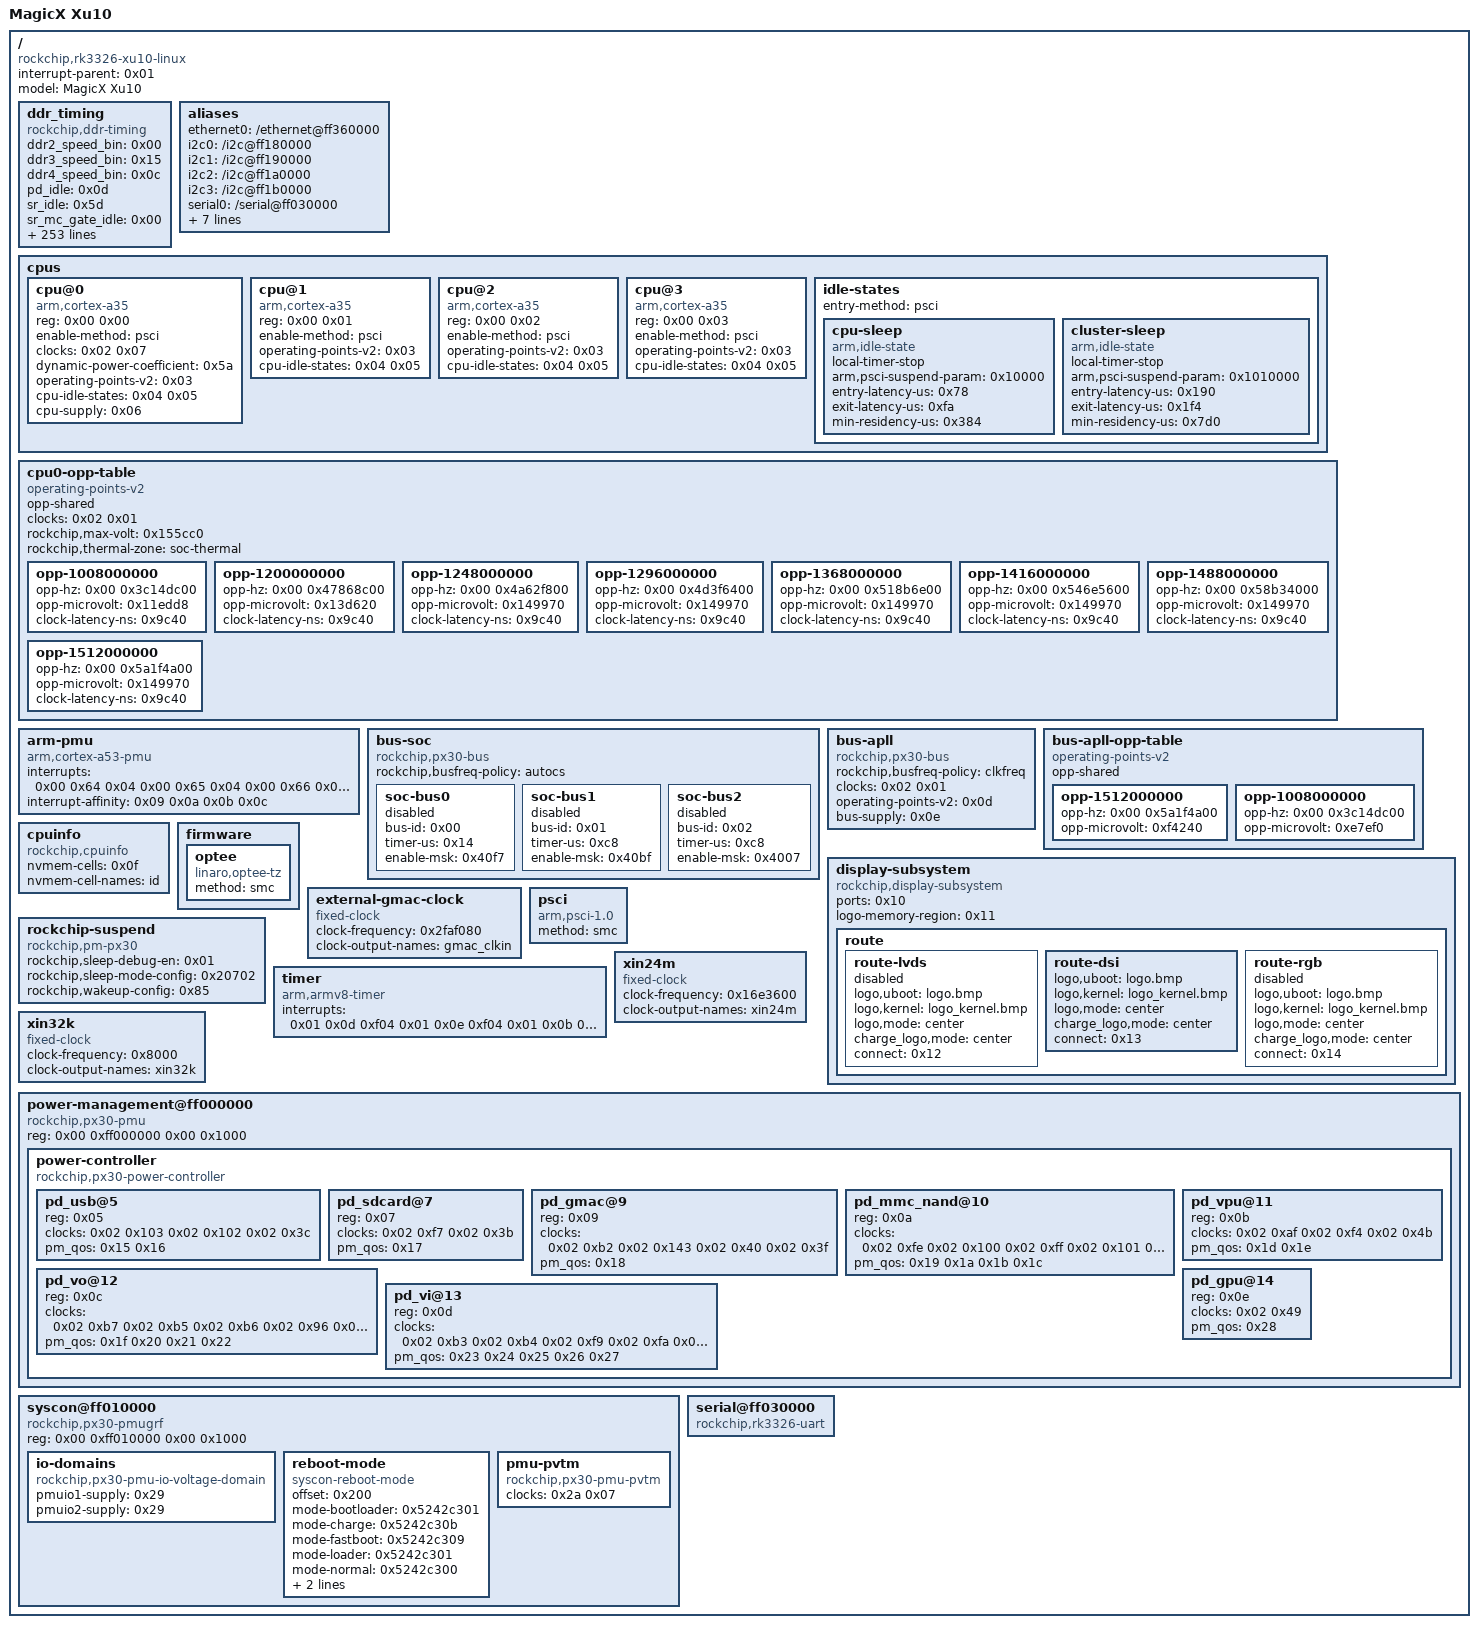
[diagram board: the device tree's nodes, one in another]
/dts-v1/;

/ {
	compatible = "rockchip,rk3326-xu10-linux\0rockchip,rk3326";
	interrupt-parent = <0x01>;
	#address-cells = <0x02>;
	#size-cells = <0x02>;
	model = "MagicX Xu10";

	ddr_timing {
		compatible = "rockchip,ddr-timing";
		ddr2_speed_bin = <0x00>;
		ddr3_speed_bin = <0x15>;
		ddr4_speed_bin = <0x0c>;
		pd_idle = <0x0d>;
		sr_idle = <0x5d>;
		sr_mc_gate_idle = <0x00>;
		srpd_lite_idle = <0x00>;
		standby_idle = <0x00>;
		auto_pd_dis_freq = <0x42a>;
		auto_sr_dis_freq = <0x320>;
		ddr2_dll_dis_freq = <0x12c>;
		ddr3_dll_dis_freq = <0x12c>;
		ddr4_dll_dis_freq = <0x271>;
		phy_dll_dis_freq = <0x190>;
		ddr2_odt_dis_freq = <0x64>;
		phy_ddr2_odt_dis_freq = <0x64>;
		ddr2_drv = <0x01>;
		ddr2_odt = <0x96>;
		phy_ddr2_ca_drv = <0x15>;
		phy_ddr2_ck_drv = <0x12>;
		phy_ddr2_dq_drv = <0x15>;
		phy_ddr2_odt = <0x02>;
		ddr3_odt_dis_freq = <0x190>;
		phy_ddr3_odt_dis_freq = <0x190>;
		ddr3_drv = <0x28>;
		ddr3_odt = <0x78>;
		phy_ddr3_ca_drv = <0x15>;
		phy_ddr3_ck_drv = <0x12>;
		phy_ddr3_dq_drv = <0x15>;
		phy_ddr3_odt = <0x02>;
		phy_lpddr2_odt_dis_freq = <0x29a>;
		lpddr2_drv = <0x28>;
		phy_lpddr2_ca_drv = <0x16>;
		phy_lpddr2_ck_drv = <0x13>;
		phy_lpddr2_dq_drv = <0x16>;
		phy_lpddr2_odt = <0x00>;
		lpddr3_odt_dis_freq = <0x190>;
		phy_lpddr3_odt_dis_freq = <0x190>;
		lpddr3_drv = <0x28>;
		lpddr3_odt = <0xf0>;
		phy_lpddr3_ca_drv = <0x16>;
		phy_lpddr3_ck_drv = <0x13>;
		phy_lpddr3_dq_drv = <0x16>;
		phy_lpddr3_odt = <0x02>;
		lpddr4_odt_dis_freq = <0x320>;
		phy_lpddr4_odt_dis_freq = <0x320>;
		lpddr4_drv = <0x3c>;
		lpddr4_dq_odt = <0x28>;
		lpddr4_ca_odt = <0x28>;
		phy_lpddr4_ca_drv = <0x14>;
		phy_lpddr4_ck_cs_drv = <0x06>;
		phy_lpddr4_dq_drv = <0x06>;
		phy_lpddr4_odt = <0x10>;
		ddr4_odt_dis_freq = <0x29a>;
		phy_ddr4_odt_dis_freq = <0x29a>;
		ddr4_drv = <0x22>;
		ddr4_odt = <0xf0>;
		phy_ddr4_ca_drv = <0x16>;
		phy_ddr4_ck_drv = <0x13>;
		phy_ddr4_dq_drv = <0x16>;
		phy_ddr4_odt = <0x02>;
		ddr3a1_ddr4a9_de-skew = <0x06>;
		ddr3a0_ddr4a10_de-skew = <0x07>;
		ddr3a3_ddr4a6_de-skew = <0x07>;
		ddr3a2_ddr4a4_de-skew = <0x07>;
		ddr3a5_dd4a8_de-skew = <0x07>;
		ddr3a4_ddr4a5_de-skew = <0x07>;
		ddr3a7_ddr4a11_de-skew = <0x07>;
		ddr3a6_ddr4a7_de-skew = <0x06>;
		ddr3a9_ddr4a0_de-skew = <0x07>;
		ddr3a8_ddr4a13_de-skew = <0x07>;
		ddr3a11_ddr4a3_de-skew = <0x07>;
		ddr3a10_ddr4cs0_de-skew = <0x07>;
		ddr3a13_ddr4a2_de-skew = <0x07>;
		ddr3a12_ddr4ba1_de-skew = <0x07>;
		ddr3a15_ddr4odt0_de-skew = <0x07>;
		ddr3a14_ddr4a1_de-skew = <0x07>;
		ddr3ba1_ddr4a15_de-skew = <0x07>;
		ddr3ba0_ddr4bg0_de-skew = <0x07>;
		ddr3ras_ddr4cke_de-skew = <0x07>;
		ddr3ba2_ddr4ba0_de-skew = <0x07>;
		ddr3we_ddr4bg1_de-skew = <0x07>;
		ddr3cas_ddr4a12_de-skew = <0x07>;
		ddr3ckn_ddr4ckn_de-skew = <0x07>;
		ddr3ckp_ddr4ckp_de-skew = <0x07>;
		ddr3cke_ddr4a16_de-skew = <0x07>;
		ddr3odt0_ddr4a14_de-skew = <0x07>;
		ddr3cs0_ddr4act_de-skew = <0x06>;
		ddr3reset_ddr4reset_de-skew = <0x07>;
		ddr3cs1_ddr4cs1_de-skew = <0x06>;
		ddr3odt1_ddr4odt1_de-skew = <0x07>;
		cs0_dm0_rx_de-skew = <0x07>;
		cs0_dm0_tx_de-skew = <0x07>;
		cs0_dq0_rx_de-skew = <0x08>;
		cs0_dq0_tx_de-skew = <0x08>;
		cs0_dq1_rx_de-skew = <0x09>;
		cs0_dq1_tx_de-skew = <0x08>;
		cs0_dq2_rx_de-skew = <0x08>;
		cs0_dq2_tx_de-skew = <0x08>;
		cs0_dq3_rx_de-skew = <0x08>;
		cs0_dq3_tx_de-skew = <0x08>;
		cs0_dq4_rx_de-skew = <0x09>;
		cs0_dq4_tx_de-skew = <0x08>;
		cs0_dq5_rx_de-skew = <0x09>;
		cs0_dq5_tx_de-skew = <0x08>;
		cs0_dq6_rx_de-skew = <0x09>;
		cs0_dq6_tx_de-skew = <0x08>;
		cs0_dq7_rx_de-skew = <0x08>;
		cs0_dq7_tx_de-skew = <0x08>;
		cs0_dqs0_rx_de-skew = <0x06>;
		cs0_dqs0p_tx_de-skew = <0x09>;
		cs0_dqs0n_tx_de-skew = <0x09>;
		cs0_dm1_rx_de-skew = <0x07>;
		cs0_dm1_tx_de-skew = <0x06>;
		cs0_dq8_rx_de-skew = <0x08>;
		cs0_dq8_tx_de-skew = <0x07>;
		cs0_dq9_rx_de-skew = <0x09>;
		cs0_dq9_tx_de-skew = <0x07>;
		cs0_dq10_rx_de-skew = <0x08>;
		cs0_dq10_tx_de-skew = <0x08>;
		cs0_dq11_rx_de-skew = <0x08>;
		cs0_dq11_tx_de-skew = <0x07>;
		cs0_dq12_rx_de-skew = <0x08>;
		cs0_dq12_tx_de-skew = <0x08>;
		cs0_dq13_rx_de-skew = <0x09>;
		cs0_dq13_tx_de-skew = <0x07>;
		cs0_dq14_rx_de-skew = <0x09>;
		cs0_dq14_tx_de-skew = <0x08>;
		cs0_dq15_rx_de-skew = <0x09>;
		cs0_dq15_tx_de-skew = <0x07>;
		cs0_dqs1_rx_de-skew = <0x07>;
		cs0_dqs1p_tx_de-skew = <0x09>;
		cs0_dqs1n_tx_de-skew = <0x09>;
		cs0_dm2_rx_de-skew = <0x07>;
		cs0_dm2_tx_de-skew = <0x07>;
		cs0_dq16_rx_de-skew = <0x09>;
		cs0_dq16_tx_de-skew = <0x09>;
		cs0_dq17_rx_de-skew = <0x07>;
		cs0_dq17_tx_de-skew = <0x09>;
		cs0_dq18_rx_de-skew = <0x07>;
		cs0_dq18_tx_de-skew = <0x08>;
		cs0_dq19_rx_de-skew = <0x07>;
		cs0_dq19_tx_de-skew = <0x09>;
		cs0_dq20_rx_de-skew = <0x09>;
		cs0_dq20_tx_de-skew = <0x09>;
		cs0_dq21_rx_de-skew = <0x09>;
		cs0_dq21_tx_de-skew = <0x09>;
		cs0_dq22_rx_de-skew = <0x08>;
		cs0_dq22_tx_de-skew = <0x09>;
		cs0_dq23_rx_de-skew = <0x08>;
		cs0_dq23_tx_de-skew = <0x09>;
		cs0_dqs2_rx_de-skew = <0x06>;
		cs0_dqs2p_tx_de-skew = <0x09>;
		cs0_dqs2n_tx_de-skew = <0x09>;
		cs0_dm3_rx_de-skew = <0x07>;
		cs0_dm3_tx_de-skew = <0x07>;
		cs0_dq24_rx_de-skew = <0x08>;
		cs0_dq24_tx_de-skew = <0x08>;
		cs0_dq25_rx_de-skew = <0x09>;
		cs0_dq25_tx_de-skew = <0x09>;
		cs0_dq26_rx_de-skew = <0x09>;
		cs0_dq26_tx_de-skew = <0x08>;
		cs0_dq27_rx_de-skew = <0x09>;
		cs0_dq27_tx_de-skew = <0x08>;
		cs0_dq28_rx_de-skew = <0x09>;
		cs0_dq28_tx_de-skew = <0x09>;
		cs0_dq29_rx_de-skew = <0x09>;
		cs0_dq29_tx_de-skew = <0x09>;
		cs0_dq30_rx_de-skew = <0x08>;
		cs0_dq30_tx_de-skew = <0x08>;
		cs0_dq31_rx_de-skew = <0x08>;
		cs0_dq31_tx_de-skew = <0x08>;
		cs0_dqs3_rx_de-skew = <0x07>;
		cs0_dqs3p_tx_de-skew = <0x09>;
		cs0_dqs3n_tx_de-skew = <0x09>;
		cs1_dm0_rx_de-skew = <0x07>;
		cs1_dm0_tx_de-skew = <0x07>;
		cs1_dq0_rx_de-skew = <0x08>;
		cs1_dq0_tx_de-skew = <0x08>;
		cs1_dq1_rx_de-skew = <0x09>;
		cs1_dq1_tx_de-skew = <0x08>;
		cs1_dq2_rx_de-skew = <0x08>;
		cs1_dq2_tx_de-skew = <0x08>;
		cs1_dq3_rx_de-skew = <0x08>;
		cs1_dq3_tx_de-skew = <0x08>;
		cs1_dq4_rx_de-skew = <0x08>;
		cs1_dq4_tx_de-skew = <0x08>;
		cs1_dq5_rx_de-skew = <0x09>;
		cs1_dq5_tx_de-skew = <0x08>;
		cs1_dq6_rx_de-skew = <0x09>;
		cs1_dq6_tx_de-skew = <0x08>;
		cs1_dq7_rx_de-skew = <0x08>;
		cs1_dq7_tx_de-skew = <0x08>;
		cs1_dqs0_rx_de-skew = <0x06>;
		cs1_dqs0p_tx_de-skew = <0x09>;
		cs1_dqs0n_tx_de-skew = <0x09>;
		cs1_dm1_rx_de-skew = <0x07>;
		cs1_dm1_tx_de-skew = <0x07>;
		cs1_dq8_rx_de-skew = <0x08>;
		cs1_dq8_tx_de-skew = <0x08>;
		cs1_dq9_rx_de-skew = <0x08>;
		cs1_dq9_tx_de-skew = <0x07>;
		cs1_dq10_rx_de-skew = <0x07>;
		cs1_dq10_tx_de-skew = <0x08>;
		cs1_dq11_rx_de-skew = <0x08>;
		cs1_dq11_tx_de-skew = <0x08>;
		cs1_dq12_rx_de-skew = <0x08>;
		cs1_dq12_tx_de-skew = <0x07>;
		cs1_dq13_rx_de-skew = <0x08>;
		cs1_dq13_tx_de-skew = <0x08>;
		cs1_dq14_rx_de-skew = <0x08>;
		cs1_dq14_tx_de-skew = <0x08>;
		cs1_dq15_rx_de-skew = <0x08>;
		cs1_dq15_tx_de-skew = <0x07>;
		cs1_dqs1_rx_de-skew = <0x07>;
		cs1_dqs1p_tx_de-skew = <0x09>;
		cs1_dqs1n_tx_de-skew = <0x09>;
		cs1_dm2_rx_de-skew = <0x07>;
		cs1_dm2_tx_de-skew = <0x08>;
		cs1_dq16_rx_de-skew = <0x08>;
		cs1_dq16_tx_de-skew = <0x09>;
		cs1_dq17_rx_de-skew = <0x08>;
		cs1_dq17_tx_de-skew = <0x09>;
		cs1_dq18_rx_de-skew = <0x07>;
		cs1_dq18_tx_de-skew = <0x08>;
		cs1_dq19_rx_de-skew = <0x08>;
		cs1_dq19_tx_de-skew = <0x09>;
		cs1_dq20_rx_de-skew = <0x09>;
		cs1_dq20_tx_de-skew = <0x09>;
		cs1_dq21_rx_de-skew = <0x09>;
		cs1_dq21_tx_de-skew = <0x09>;
		cs1_dq22_rx_de-skew = <0x08>;
		cs1_dq22_tx_de-skew = <0x09>;
		cs1_dq23_rx_de-skew = <0x08>;
		cs1_dq23_tx_de-skew = <0x09>;
		cs1_dqs2_rx_de-skew = <0x06>;
		cs1_dqs2p_tx_de-skew = <0x09>;
		cs1_dqs2n_tx_de-skew = <0x09>;
		cs1_dm3_rx_de-skew = <0x07>;
		cs1_dm3_tx_de-skew = <0x07>;
		cs1_dq24_rx_de-skew = <0x08>;
		cs1_dq24_tx_de-skew = <0x09>;
		cs1_dq25_rx_de-skew = <0x09>;
		cs1_dq25_tx_de-skew = <0x09>;
		cs1_dq26_rx_de-skew = <0x09>;
		cs1_dq26_tx_de-skew = <0x08>;
		cs1_dq27_rx_de-skew = <0x08>;
		cs1_dq27_tx_de-skew = <0x08>;
		cs1_dq28_rx_de-skew = <0x09>;
		cs1_dq28_tx_de-skew = <0x09>;
		cs1_dq29_rx_de-skew = <0x09>;
		cs1_dq29_tx_de-skew = <0x09>;
		cs1_dq30_rx_de-skew = <0x09>;
		cs1_dq30_tx_de-skew = <0x08>;
		cs1_dq31_rx_de-skew = <0x08>;
		cs1_dq31_tx_de-skew = <0x08>;
		cs1_dqs3_rx_de-skew = <0x07>;
		cs1_dqs3p_tx_de-skew = <0x09>;
		cs1_dqs3n_tx_de-skew = <0x09>;
		phandle = <0xb0>;
	};

	aliases {
		ethernet0 = "/ethernet@ff360000";
		i2c0 = "/i2c@ff180000";
		i2c1 = "/i2c@ff190000";
		i2c2 = "/i2c@ff1a0000";
		i2c3 = "/i2c@ff1b0000";
		serial0 = "/serial@ff030000";
		serial1 = "/serial@ff158000";
		serial2 = "/serial@ff160000";
		serial3 = "/serial@ff168000";
		serial4 = "/serial@ff170000";
		serial5 = "/serial@ff178000";
		spi0 = "/spi@ff1d0000";
		spi1 = "/spi@ff1d8000";
	};

	cpus {
		#address-cells = <0x02>;
		#size-cells = <0x00>;

		cpu@0 {
			device_type = "cpu";
			compatible = "arm,cortex-a35\0arm,armv8";
			reg = <0x00 0x00>;
			enable-method = "psci";
			clocks = <0x02 0x07>;
			#cooling-cells = <0x02>;
			dynamic-power-coefficient = <0x5a>;
			operating-points-v2 = <0x03>;
			cpu-idle-states = <0x04 0x05>;
			cpu-supply = <0x06>;
			phandle = <0x09>;
		};

		cpu@1 {
			device_type = "cpu";
			compatible = "arm,cortex-a35\0arm,armv8";
			reg = <0x00 0x01>;
			enable-method = "psci";
			operating-points-v2 = <0x03>;
			cpu-idle-states = <0x04 0x05>;
			phandle = <0x0a>;
		};

		cpu@2 {
			device_type = "cpu";
			compatible = "arm,cortex-a35\0arm,armv8";
			reg = <0x00 0x02>;
			enable-method = "psci";
			operating-points-v2 = <0x03>;
			cpu-idle-states = <0x04 0x05>;
			phandle = <0x0b>;
		};

		cpu@3 {
			device_type = "cpu";
			compatible = "arm,cortex-a35\0arm,armv8";
			reg = <0x00 0x03>;
			enable-method = "psci";
			operating-points-v2 = <0x03>;
			cpu-idle-states = <0x04 0x05>;
			phandle = <0x0c>;
		};

		idle-states {
			entry-method = "psci";

			cpu-sleep {
				compatible = "arm,idle-state";
				local-timer-stop;
				arm,psci-suspend-param = <0x10000>;
				entry-latency-us = <0x78>;
				exit-latency-us = <0xfa>;
				min-residency-us = <0x384>;
				phandle = <0x04>;
			};

			cluster-sleep {
				compatible = "arm,idle-state";
				local-timer-stop;
				arm,psci-suspend-param = <0x1010000>;
				entry-latency-us = <0x190>;
				exit-latency-us = <0x1f4>;
				min-residency-us = <0x7d0>;
				phandle = <0x05>;
			};
		};
	};

	cpu0-opp-table {
		compatible = "operating-points-v2";
		opp-shared;
		clocks = <0x02 0x01>;
		rockchip,max-volt = <0x155cc0>;
		rockchip,thermal-zone = "soc-thermal";
		phandle = <0x03>;

		opp-1008000000 {
			opp-hz = <0x00 0x3c14dc00>;
			opp-microvolt = <0x11edd8>;
			clock-latency-ns = <0x9c40>;
		};

		opp-1200000000 {
			opp-hz = <0x00 0x47868c00>;
			opp-microvolt = <0x13d620>;
			clock-latency-ns = <0x9c40>;
		};

		opp-1248000000 {
			opp-hz = <0x00 0x4a62f800>;
			opp-microvolt = <0x149970>;
			clock-latency-ns = <0x9c40>;
		};

		opp-1296000000 {
			opp-hz = <0x00 0x4d3f6400>;
			opp-microvolt = <0x149970>;
			clock-latency-ns = <0x9c40>;
		};

		opp-1368000000 {
			opp-hz = <0x00 0x518b6e00>;
			opp-microvolt = <0x149970>;
			clock-latency-ns = <0x9c40>;
		};

		opp-1416000000 {
			opp-hz = <0x00 0x546e5600>;
			opp-microvolt = <0x149970>;
			clock-latency-ns = <0x9c40>;
		};

		opp-1488000000 {
			opp-hz = <0x00 0x58b34000>;
			opp-microvolt = <0x149970>;
			clock-latency-ns = <0x9c40>;
		};

		opp-1512000000 {
			opp-hz = <0x00 0x5a1f4a00>;
			opp-microvolt = <0x149970>;
			clock-latency-ns = <0x9c40>;
		};
	};

	arm-pmu {
		compatible = "arm,cortex-a53-pmu";
		interrupts = <0x00 0x64 0x04 0x00 0x65 0x04 0x00 0x66 0x04 0x00 0x67 0x04>;
		interrupt-affinity = <0x09 0x0a 0x0b 0x0c>;
	};

	bus-soc {
		compatible = "rockchip,px30-bus";
		rockchip,busfreq-policy = "autocs";
		phandle = <0xc4>;

		soc-bus0 {
			bus-id = <0x00>;
			timer-us = <0x14>;
			enable-msk = <0x40f7>;
			status = "disabled";
		};

		soc-bus1 {
			bus-id = <0x01>;
			timer-us = <0xc8>;
			enable-msk = <0x40bf>;
			status = "disabled";
		};

		soc-bus2 {
			bus-id = <0x02>;
			timer-us = <0xc8>;
			enable-msk = <0x4007>;
			status = "disabled";
		};
	};

	bus-apll {
		compatible = "rockchip,px30-bus";
		rockchip,busfreq-policy = "clkfreq";
		clocks = <0x02 0x01>;
		clock-names = "bus";
		operating-points-v2 = <0x0d>;
		status = "okay";
		bus-supply = <0x0e>;
		phandle = <0xc5>;
	};

	bus-apll-opp-table {
		compatible = "operating-points-v2";
		opp-shared;
		phandle = <0x0d>;

		opp-1512000000 {
			opp-hz = <0x00 0x5a1f4a00>;
			opp-microvolt = <0xf4240>;
		};

		opp-1008000000 {
			opp-hz = <0x00 0x3c14dc00>;
			opp-microvolt = <0xe7ef0>;
		};
	};

	cpuinfo {
		compatible = "rockchip,cpuinfo";
		nvmem-cells = <0x0f>;
		nvmem-cell-names = "id";
	};

	display-subsystem {
		compatible = "rockchip,display-subsystem";
		ports = <0x10>;
		status = "okay";
		logo-memory-region = <0x11>;
		phandle = <0xc6>;

		route {

			route-lvds {
				status = "disabled";
				logo,uboot = "logo.bmp";
				logo,kernel = "logo_kernel.bmp";
				logo,mode = "center";
				charge_logo,mode = "center";
				connect = <0x12>;
				phandle = <0xc7>;
			};

			route-dsi {
				status = "okay";
				logo,uboot = "logo.bmp";
				logo,kernel = "logo_kernel.bmp";
				logo,mode = "center";
				charge_logo,mode = "center";
				connect = <0x13>;
				phandle = <0xc8>;
			};

			route-rgb {
				status = "disabled";
				logo,uboot = "logo.bmp";
				logo,kernel = "logo_kernel.bmp";
				logo,mode = "center";
				charge_logo,mode = "center";
				connect = <0x14>;
				phandle = <0xc9>;
			};
		};
	};

	firmware {

		optee {
			compatible = "linaro,optee-tz";
			method = "smc";
		};
	};

	external-gmac-clock {
		compatible = "fixed-clock";
		clock-frequency = <0x2faf080>;
		clock-output-names = "gmac_clkin";
		#clock-cells = <0x00>;
		phandle = <0xca>;
	};

	psci {
		compatible = "arm,psci-1.0";
		method = "smc";
	};

	rockchip-suspend {
		compatible = "rockchip,pm-px30";
		status = "okay";
		rockchip,sleep-debug-en = <0x01>;
		rockchip,sleep-mode-config = <0x20702>;
		rockchip,wakeup-config = <0x85>;
		phandle = <0xcb>;
	};

	timer {
		compatible = "arm,armv8-timer";
		interrupts = <0x01 0x0d 0xf04 0x01 0x0e 0xf04 0x01 0x0b 0xf04 0x01 0x0a 0xf04>;
	};

	xin24m {
		compatible = "fixed-clock";
		#clock-cells = <0x00>;
		clock-frequency = <0x16e3600>;
		clock-output-names = "xin24m";
		phandle = <0xcc>;
	};

	xin32k {
		compatible = "fixed-clock";
		#clock-cells = <0x00>;
		clock-frequency = <0x8000>;
		clock-output-names = "xin32k";
		phandle = <0xcd>;
	};

	power-management@ff000000 {
		compatible = "rockchip,px30-pmu\0syscon\0simple-mfd";
		reg = <0x00 0xff000000 0x00 0x1000>;
		phandle = <0xce>;

		power-controller {
			compatible = "rockchip,px30-power-controller";
			#power-domain-cells = <0x01>;
			#address-cells = <0x01>;
			#size-cells = <0x00>;
			phandle = <0x8b>;

			pd_usb@5 {
				reg = <0x05>;
				clocks = <0x02 0x103 0x02 0x102 0x02 0x3c>;
				pm_qos = <0x15 0x16>;
			};

			pd_sdcard@7 {
				reg = <0x07>;
				clocks = <0x02 0xf7 0x02 0x3b>;
				pm_qos = <0x17>;
			};

			pd_gmac@9 {
				reg = <0x09>;
				clocks = <0x02 0xb2 0x02 0x143 0x02 0x40 0x02 0x3f>;
				pm_qos = <0x18>;
			};

			pd_mmc_nand@10 {
				reg = <0x0a>;
				clocks = <0x02 0xfe 0x02 0x100 0x02 0xff 0x02 0x101 0x02 0x39 0x02 0x37 0x02 0x38 0x02 0x3a>;
				pm_qos = <0x19 0x1a 0x1b 0x1c>;
			};

			pd_vpu@11 {
				reg = <0x0b>;
				clocks = <0x02 0xaf 0x02 0xf4 0x02 0x4b>;
				pm_qos = <0x1d 0x1e>;
			};

			pd_vo@12 {
				reg = <0x0c>;
				clocks = <0x02 0xb7 0x02 0xb5 0x02 0xb6 0x02 0x96 0x02 0x97 0x02 0xfd 0x02 0xfb 0x02 0xfc 0x02 0x144 0x02 0x35 0x02 0x36>;
				pm_qos = <0x1f 0x20 0x21 0x22>;
			};

			pd_vi@13 {
				reg = <0x0d>;
				clocks = <0x02 0xb3 0x02 0xb4 0x02 0xf9 0x02 0xfa 0x02 0x33>;
				pm_qos = <0x23 0x24 0x25 0x26 0x27>;
			};

			pd_gpu@14 {
				reg = <0x0e>;
				clocks = <0x02 0x49>;
				pm_qos = <0x28>;
			};
		};
	};

	syscon@ff010000 {
		compatible = "rockchip,px30-pmugrf\0syscon\0simple-mfd";
		reg = <0x00 0xff010000 0x00 0x1000>;
		#address-cells = <0x01>;
		#size-cells = <0x01>;
		phandle = <0xad>;

		io-domains {
			compatible = "rockchip,px30-pmu-io-voltage-domain";
			status = "okay";
			pmuio1-supply = <0x29>;
			pmuio2-supply = <0x29>;
			phandle = <0xcf>;
		};

		reboot-mode {
			compatible = "syscon-reboot-mode";
			offset = <0x200>;
			mode-bootloader = <0x5242c301>;
			mode-charge = <0x5242c30b>;
			mode-fastboot = <0x5242c309>;
			mode-loader = <0x5242c301>;
			mode-normal = <0x5242c300>;
			mode-recovery = <0x5242c303>;
			mode-ums = <0x5242c30c>;
		};

		pmu-pvtm {
			compatible = "rockchip,px30-pmu-pvtm";
			clocks = <0x2a 0x07>;
			clock-names = "pmu";
			status = "okay";
			phandle = <0xd0>;
		};
	};

	serial@ff030000 {
		compatible = "rockchip,rk3326-uart\0snps,dw-apb-uart";
		status = "okay";
	};
};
